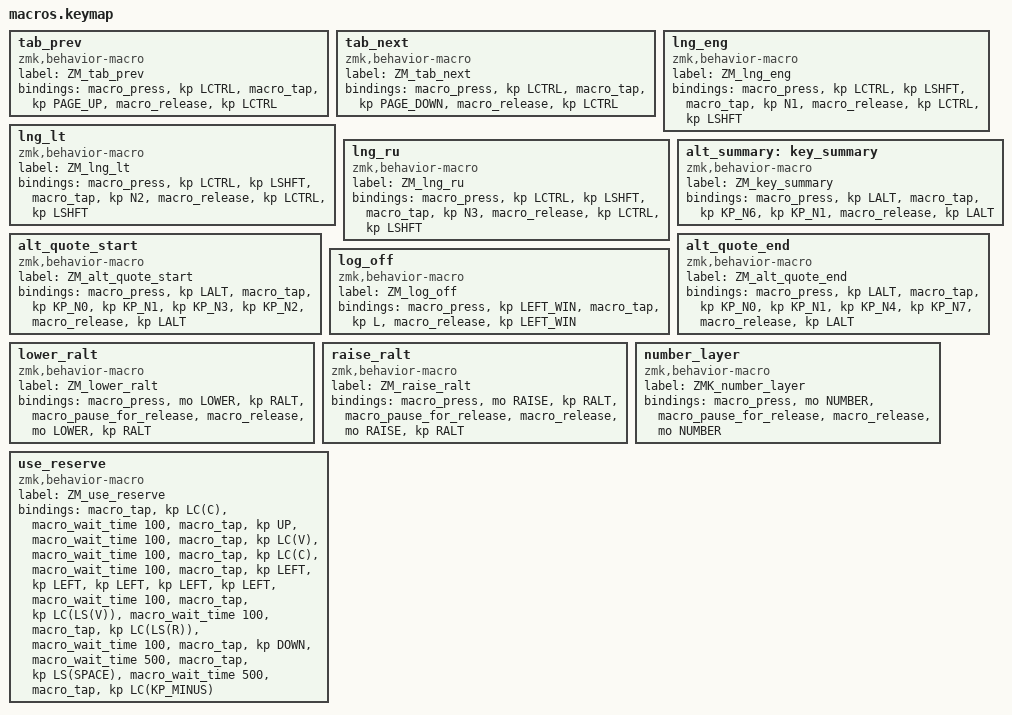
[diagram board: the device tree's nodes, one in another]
tab_prev: tab_prev {
        label = "ZM_tab_prev";
        compatible = "zmk,behavior-macro";
        #binding-cells = <0>;
        bindings
                = <&macro_press &kp LCTRL>
                , <&macro_tap &kp PAGE_UP>
                , <&macro_release &kp LCTRL>;
};

tab_next: tab_next {
        label = "ZM_tab_next";
        compatible = "zmk,behavior-macro";
        #binding-cells = <0>;
        bindings
                = <&macro_press &kp LCTRL>
                , <&macro_tap &kp PAGE_DOWN>
                , <&macro_release &kp LCTRL>;
};

lng_eng: lng_eng {
        label = "ZM_lng_eng";
        compatible = "zmk,behavior-macro";
        #binding-cells = <0>;
        bindings
                = <&macro_press &kp LCTRL &kp LSHFT>
                , <&macro_tap &kp N1>
                , <&macro_release &kp LCTRL &kp LSHFT>;
};

lng_lt: lng_lt {
        label = "ZM_lng_lt";
        compatible = "zmk,behavior-macro";
        #binding-cells = <0>;
        bindings
                = <&macro_press &kp LCTRL &kp LSHFT>
                , <&macro_tap &kp N2>
                , <&macro_release &kp LCTRL &kp LSHFT>;
};

lng_ru: lng_ru {
        label = "ZM_lng_ru";
        compatible = "zmk,behavior-macro";
        #binding-cells = <0>;
        bindings
                = <&macro_press &kp LCTRL &kp LSHFT>
                , <&macro_tap &kp N3>
                , <&macro_release &kp LCTRL &kp LSHFT>;
};

alt_summary: key_summary {
        label = "ZM_key_summary";
        compatible = "zmk,behavior-macro";
        #binding-cells = <0>;
        bindings
                = <&macro_press &kp LALT>
                , <&macro_tap &kp KP_N6 &kp KP_N1>
                , <&macro_release &kp LALT>;
};

alt_quote_start: alt_quote_start {
        label = "ZM_alt_quote_start";
        compatible = "zmk,behavior-macro";
        #binding-cells = <0>;
        bindings
                = <&macro_press &kp LALT>
                , <&macro_tap &kp KP_N0 &kp KP_N1 &kp KP_N3 &kp KP_N2>
                , <&macro_release &kp LALT>;
};

alt_quote_end: alt_quote_end {
        label = "ZM_alt_quote_end";
        compatible = "zmk,behavior-macro";
        #binding-cells = <0>;
        bindings
                = <&macro_press &kp LALT>
                , <&macro_tap &kp KP_N0 &kp KP_N1 &kp KP_N4 &kp KP_N7>
                , <&macro_release &kp LALT>;
};

log_off: log_off {
        label = "ZM_log_off";
        compatible = "zmk,behavior-macro";
        #binding-cells = <0>;
        bindings
                = <&macro_press &kp LEFT_WIN>
                , <&macro_tap &kp L>
                , <&macro_release &kp LEFT_WIN>;
};

lower_ralt: lower_ralt {
        label = "ZM_lower_ralt";
        compatible = "zmk,behavior-macro";
        #binding-cells = <0>;
        bindings
                = <&macro_press &mo LOWER &kp RALT>
                , <&macro_pause_for_release>
                , <&macro_release &mo LOWER &kp RALT>;
};

raise_ralt: raise_ralt {
        label = "ZM_raise_ralt";
        compatible = "zmk,behavior-macro";
        #binding-cells = <0>;
        bindings
                = <&macro_press &mo RAISE &kp RALT>
                , <&macro_pause_for_release>
                , <&macro_release &mo RAISE &kp RALT>;
};

number_layer: number_layer {
        label = "ZMK_number_layer";
        compatible = "zmk,behavior-macro";
        #binding-cells = <0>;
        bindings
                = <&macro_press &mo NUMBER>
                , <&macro_pause_for_release>
                , <&macro_release &mo NUMBER>;
};

use_reserve: use_reserve {
        label = "ZM_use_reserve";
        compatible = "zmk,behavior-macro";
        #binding-cells = <0>;
        bindings
                = <&macro_tap &kp LC(C)>
                , <&macro_wait_time 100>
                , <&macro_tap &kp UP>
                , <&macro_wait_time 100>
                , <&macro_tap &kp LC(V)>
                , <&macro_wait_time 100>
                , <&macro_tap &kp LC(C)>
                , <&macro_wait_time 100>
                , <&macro_tap &kp LEFT &kp LEFT &kp LEFT &kp LEFT &kp LEFT>
                , <&macro_wait_time 100>
                , <&macro_tap &kp LC(LS(V))>
                , <&macro_wait_time 100>
                , <&macro_tap &kp LC(LS(R))>
                , <&macro_wait_time 100>
                , <&macro_tap &kp DOWN>
                , <&macro_wait_time 500>
                , <&macro_tap &kp LS(SPACE)>
                , <&macro_wait_time 500>
                , <&macro_tap &kp LC(KP_MINUS)>;
};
